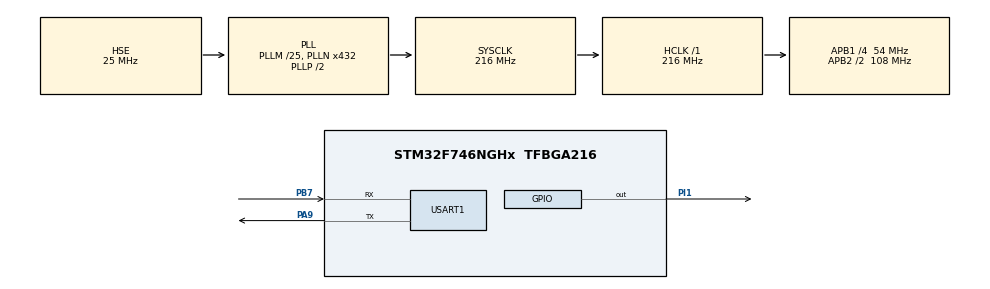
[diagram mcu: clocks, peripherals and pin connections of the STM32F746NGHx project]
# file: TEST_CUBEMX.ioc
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Mcu.Family=STM32F7
Mcu.Name=STM32F746NGHx
Mcu.Package=TFBGA216
NVIC.PriorityGroup=NVIC_PRIORITYGROUP_4
NVIC.USART1_IRQn=true\:0\:0\:false\:false\:true\:true\:true
PA9.GPIO_PuPd=GPIO_PULLUP
PA9.Mode=Asynchronous
PA9.Signal=USART1_TX
PA9.Stacked=true
PB7.GPIO_PuPd=GPIO_NOPULL
PB7.Mode=Asynchronous
PB7.Signal=USART1_RX
PH0/OSC_IN.Mode=HSE-External-Clock-Source
PH0/OSC_IN.Signal=RCC_OSC_IN
PH1/OSC_OUT.Mode=HSE-External-Clock-Source
PH1/OSC_OUT.Signal=RCC_OSC_OUT
PI1.GPIO_PuPd=GPIO_PULLUP
PI1.GPIO_Speed=GPIO_SPEED_FREQ_VERY_HIGH
PI1.Signal=GPIO_Output
PI1.Stacked=true
ProjectManager.HeapSize=0x200
ProjectManager.StackSize=0x400
ProjectManager.TargetToolchain=STM32CubeIDE
RCC.AHBFreq_Value=216000000
RCC.APB1CLKDivider=RCC_HCLK_DIV4
RCC.APB1Freq_Value=54000000
RCC.APB1TimFreq_Value=108000000
RCC.APB2CLKDivider=RCC_HCLK_DIV2
RCC.APB2Freq_Value=108000000
RCC.APB2TimFreq_Value=216000000
RCC.CortexFreq_Value=216000000
RCC.EnbaleCSS=true
RCC.HCLKFreq_Value=216000000
RCC.HSE_VALUE=25000000
RCC.HSI_VALUE=16000000
RCC.LSE_VALUE=32768
RCC.PLLM=25
RCC.PLLN=432
RCC.PLLSourceVirtual=RCC_PLLSOURCE_HSE
RCC.SYSCLKFreq_VALUE=216000000
RCC.SYSCLKSource=RCC_SYSCLKSOURCE_PLLCLK
RCC.USBFreq_Value=216000000
RCC.VCOOutputFreq_Value=432000000
USART1.VirtualMode-Asynchronous=VM_ASYNC
board=custom

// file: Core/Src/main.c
/* USER CODE BEGIN Header */
/**
  ******************************************************************************
  * @file           : main.c
  * @brief          : Main program body
  ******************************************************************************
  * @attention
  *
  * <h2><center>&copy; Copyright (c) 2021 STMicroelectronics.
  * All rights reserved.</center></h2>
  *
  * This software component is licensed by ST under BSD 3-Clause license,
  * the "License"; You may not use this file except in compliance with the
  * License. You may obtain a copy of the License at:
  *                        opensource.org/licenses/BSD-3-Clause
  *
  ******************************************************************************
  */
/* USER CODE END Header */
#include "main.h"

/* USER CODE BEGIN Includes */
#include <string.h>
/* USER CODE END Includes */

/* USER CODE BEGIN PM */
#define BUF_SIZE	(1000)

/* USER CODE END PM */

UART_HandleTypeDef huart1;

/* USER CODE BEGIN PV */
char character = 0;
static char buffer[BUF_SIZE];

/* USER CODE END PV */

void SystemClock_Config(void);
static void MX_GPIO_Init(void);
static void MX_USART1_UART_Init(void);
/* USER CODE BEGIN PFP */
void delay(const unsigned int count);
void executeCmd(const uint8_t* cmd);
/* USER CODE END PFP */

/* USER CODE BEGIN 0 */
void delay(const unsigned int count)
{
	for(uint32_t i = 0; i < count; i++);
}

void executeCmd(const uint8_t* cmd)
{
  uint32_t len = strlen((const char*)(cmd)) - 1;
  uint8_t help_prompt[]  = "This is help command.\r\r#";
  uint8_t error_prompt[] = "This is a wrong command.\r\r#";
  if (strncmp((const char*)(cmd), "help", len) == 0) {
    HAL_UART_Transmit(&huart1, help_prompt, strlen((const char*)(help_prompt)), HAL_MAX_DELAY);
  } else {
    HAL_UART_Transmit(&huart1, error_prompt, strlen((const char*)(error_prompt)), HAL_MAX_DELAY);
  }
}
/* USER CODE END 0 */

int main(void)
{

  /* MCU Configuration--------------------------------------------------------*/

  /* Reset of all peripherals, Initializes the Flash interface and the Systick. */
  HAL_Init();

  /* Configure the system clock */
  SystemClock_Config();

  /* Initialize all configured peripherals */
  MX_GPIO_Init();
  MX_USART1_UART_Init();
  /* USER CODE BEGIN 2 */
  uint8_t banner[] = "Welcome to STM32F746G-DISCO !\r#";
  HAL_UART_Transmit(&huart1, banner, strlen((const char*)(banner)), HAL_MAX_DELAY);
  __HAL_UART_ENABLE_IT(&huart1, UART_IT_RXNE);
  /* USER CODE END 2 */

  /* Infinite loop */
  /* USER CODE BEGIN WHILE */
  uint32_t index = 0;
  memset(buffer, 0x00, BUF_SIZE);
  while (1)
  {
    if (character != 0) { // character has been received
      buffer[index++] = character;
      if (character == '\r') {
        uint8_t cmd[256] = "";
        buffer[--index] = '\n';
        strcpy((char*)(cmd), buffer); // copy command text
        memset(buffer, 0x00, BUF_SIZE);
        executeCmd(cmd);
        index = 0;
      }
      character = 0;
      // flick LED1
      HAL_GPIO_TogglePin(GPIOI, GPIO_PIN_1);
      delay(1000000);
      HAL_GPIO_TogglePin(GPIOI, GPIO_PIN_1);
    }
  }
  /* USER CODE END WHILE */
}

void SystemClock_Config(void)
{
  RCC_OscInitTypeDef RCC_OscInitStruct = {0};
  RCC_ClkInitTypeDef RCC_ClkInitStruct = {0};
  RCC_PeriphCLKInitTypeDef PeriphClkInitStruct = {0};

  /** Configure the main internal regulator output voltage
  */
  __HAL_RCC_PWR_CLK_ENABLE();
  __HAL_PWR_VOLTAGESCALING_CONFIG(PWR_REGULATOR_VOLTAGE_SCALE1);
  /** Initializes the RCC Oscillators according to the specified parameters
  * in the RCC_OscInitTypeDef structure.
  */
  RCC_OscInitStruct.OscillatorType = RCC_OSCILLATORTYPE_HSE;
  RCC_OscInitStruct.HSEState = RCC_HSE_BYPASS;
  RCC_OscInitStruct.PLL.PLLState = RCC_PLL_ON;
  RCC_OscInitStruct.PLL.PLLSource = RCC_PLLSOURCE_HSE;
  RCC_OscInitStruct.PLL.PLLM = 25;
  RCC_OscInitStruct.PLL.PLLN = 432;
  RCC_OscInitStruct.PLL.PLLP = RCC_PLLP_DIV2;
  RCC_OscInitStruct.PLL.PLLQ = 2;
  if (HAL_RCC_OscConfig(&RCC_OscInitStruct) != HAL_OK)
  {
    Error_Handler();
  }
  /** Activate the Over-Drive mode
  */
  if (HAL_PWREx_EnableOverDrive() != HAL_OK)
  {
    Error_Handler();
  }
  /** Initializes the CPU, AHB and APB buses clocks
  */
  RCC_ClkInitStruct.ClockType = RCC_CLOCKTYPE_HCLK|RCC_CLOCKTYPE_SYSCLK
                              |RCC_CLOCKTYPE_PCLK1|RCC_CLOCKTYPE_PCLK2;
  RCC_ClkInitStruct.SYSCLKSource = RCC_SYSCLKSOURCE_PLLCLK;
  RCC_ClkInitStruct.AHBCLKDivider = RCC_SYSCLK_DIV1;
  RCC_ClkInitStruct.APB1CLKDivider = RCC_HCLK_DIV4;
  RCC_ClkInitStruct.APB2CLKDivider = RCC_HCLK_DIV2;

  if (HAL_RCC_ClockConfig(&RCC_ClkInitStruct, FLASH_LATENCY_7) != HAL_OK)
  {
    Error_Handler();
  }
  PeriphClkInitStruct.PeriphClockSelection = RCC_PERIPHCLK_USART1;
  PeriphClkInitStruct.Usart1ClockSelection = RCC_USART1CLKSOURCE_PCLK2;
  if (HAL_RCCEx_PeriphCLKConfig(&PeriphClkInitStruct) != HAL_OK)
  {
    Error_Handler();
  }
  /** Enables the Clock Security System
  */
  HAL_RCC_EnableCSS();
}

static void MX_USART1_UART_Init(void)
{

  huart1.Instance = USART1;
  huart1.Init.BaudRate = 115200;
  huart1.Init.WordLength = UART_WORDLENGTH_8B;
  huart1.Init.StopBits = UART_STOPBITS_1;
  huart1.Init.Parity = UART_PARITY_NONE;
  huart1.Init.Mode = UART_MODE_TX_RX;
  huart1.Init.HwFlowCtl = UART_HWCONTROL_NONE;
  huart1.Init.OverSampling = UART_OVERSAMPLING_16;
  huart1.Init.OneBitSampling = UART_ONE_BIT_SAMPLE_DISABLE;
  huart1.AdvancedInit.AdvFeatureInit = UART_ADVFEATURE_NO_INIT;
  if (HAL_UART_Init(&huart1) != HAL_OK)
  {
    Error_Handler();
  }

}

static void MX_GPIO_Init(void)
{
  GPIO_InitTypeDef GPIO_InitStruct = {0};

  /* GPIO Ports Clock Enable */
  __HAL_RCC_GPIOB_CLK_ENABLE();
  __HAL_RCC_GPIOI_CLK_ENABLE();
  __HAL_RCC_GPIOA_CLK_ENABLE();
  __HAL_RCC_GPIOH_CLK_ENABLE();

  /*Configure GPIO pin Output Level */
  HAL_GPIO_WritePin(GPIOI, GPIO_PIN_1, GPIO_PIN_RESET);

  /*Configure GPIO pin : PI1 */
  GPIO_InitStruct.Pin = GPIO_PIN_1;
  GPIO_InitStruct.Mode = GPIO_MODE_OUTPUT_PP;
  GPIO_InitStruct.Pull = GPIO_PULLUP;
  GPIO_InitStruct.Speed = GPIO_SPEED_FREQ_VERY_HIGH;
  HAL_GPIO_Init(GPIOI, &GPIO_InitStruct);

}

void Error_Handler(void)
{
  __disable_irq();
  while (1)
  {
  }
}

/************************ (C) COPYRIGHT STMicroelectronics *****END OF FILE****/
